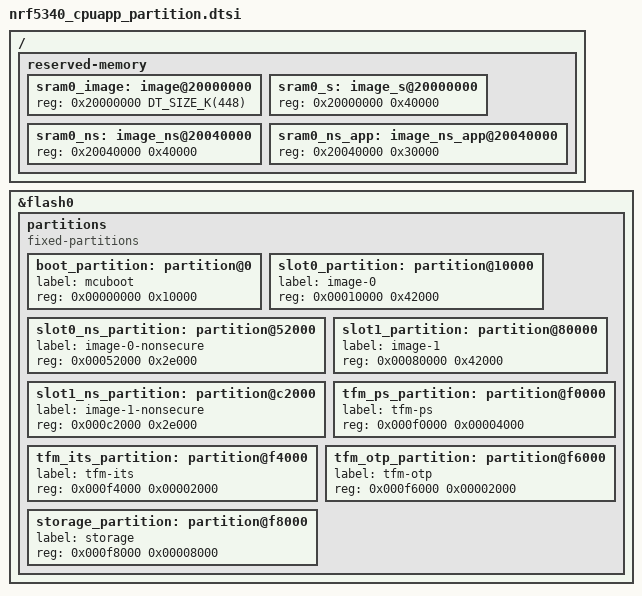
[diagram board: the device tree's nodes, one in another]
/*
 * SenseLab nRF5340 application-core logical flash/RAM layout.
 *
 * Each product uses MCUboot with equal 264 KiB primary and secondary
 * application slots. This gives PPGv2 the small amount of headroom it needs
 * over Zephyr's 256 KiB reference secure slot while retaining the same total
 * 448 KiB image areas, TF-M-reserved regions, and 32 KiB storage region.
 */

&flash0 {
	partitions {
		compatible = "fixed-partitions";
		#address-cells = <1>;
		#size-cells = <1>;

		boot_partition: partition@0 {
			label = "mcuboot";
			reg = <0x00000000 0x10000>;
		};

		slot0_partition: partition@10000 {
			label = "image-0";
			reg = <0x00010000 0x42000>;
		};

		slot0_ns_partition: partition@52000 {
			label = "image-0-nonsecure";
			reg = <0x00052000 0x2e000>;
		};

		slot1_partition: partition@80000 {
			label = "image-1";
			reg = <0x00080000 0x42000>;
		};

		slot1_ns_partition: partition@c2000 {
			label = "image-1-nonsecure";
			reg = <0x000c2000 0x2e000>;
		};

		tfm_ps_partition: partition@f0000 {
			label = "tfm-ps";
			reg = <0x000f0000 0x00004000>;
		};

		tfm_its_partition: partition@f4000 {
			label = "tfm-its";
			reg = <0x000f4000 0x00002000>;
		};

		tfm_otp_partition: partition@f6000 {
			label = "tfm-otp";
			reg = <0x000f6000 0x00002000>;
		};

		storage_partition: partition@f8000 {
			label = "storage";
			reg = <0x000f8000 0x00008000>;
		};
	};
};

/ {
	reserved-memory {
		#address-cells = <1>;
		#size-cells = <1>;
		ranges;

		sram0_image: image@20000000 {
			reg = <0x20000000 DT_SIZE_K(448)>;
		};

		sram0_s: image_s@20000000 {
			reg = <0x20000000 0x40000>;
		};

		sram0_ns: image_ns@20040000 {
			reg = <0x20040000 0x40000>;
		};

		sram0_ns_app: image_ns_app@20040000 {
			reg = <0x20040000 0x30000>;
		};
	};
};

#include <common/nordic/nrf5340_shared_sram_partition.dtsi>
